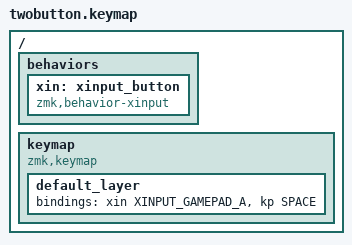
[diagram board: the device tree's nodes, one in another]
#include <behaviors.dtsi>
#include <dt-bindings/zmk/keys.h>
#include "dt-bindings/zmk/xinput.h"

/ {
    behaviors {
        xin: xinput_button {
            compatible = "zmk,behavior-xinput";
            #binding-cells = <1>;
        };
    };

    keymap {
        compatible = "zmk,keymap";

        default_layer {
            bindings = <
                &xin XINPUT_GAMEPAD_A    /* Button 0 PA1: XInput A button */
                &kp SPACE                /* Button 1 PA2: Keyboard Space  */
            >;
        };
    };
};
